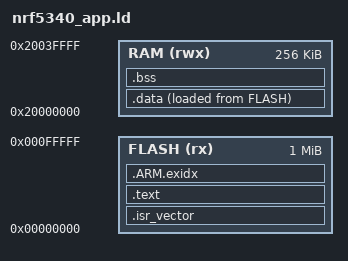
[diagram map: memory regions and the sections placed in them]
/*
 * Linker script for nRF5340 application core (baremetal, no bootloader).
 *
 * Memory map:
 *   Flash  0x00000000  1 MB   (application core code flash)
 *   RAM    0x20000000  256 KB (conservative; 512 KB available if net core unused)
 */

ENTRY(Reset_Handler)

MEMORY
{
    FLASH (rx)  : ORIGIN = 0x00000000, LENGTH = 1024K
    RAM   (rwx) : ORIGIN = 0x20000000, LENGTH = 256K
}

_estack = ORIGIN(RAM) + LENGTH(RAM);

SECTIONS
{
    .isr_vector :
    {
        . = ALIGN(4);
        KEEP(*(.isr_vector))
        . = ALIGN(4);
    } > FLASH

    .text :
    {
        . = ALIGN(4);
        *(.text*)
        *(.rodata*)
        . = ALIGN(4);
        _etext = .;
    } > FLASH

    .ARM.exidx :
    {
        *(.ARM.exidx*)
    } > FLASH

    _sidata = LOADADDR(.data);

    .data :
    {
        . = ALIGN(4);
        _sdata = .;
        *(.data*)
        . = ALIGN(4);
        _edata = .;
    } > RAM AT> FLASH

    .bss (NOLOAD) :
    {
        . = ALIGN(4);
        _sbss = .;
        *(.bss*)
        *(COMMON)
        . = ALIGN(4);
        _ebss = .;
    } > RAM
}
